# AVR128DB64 register map
Vendor: Atmel; File version: 1.0
CPU: other r0p0, little endian, no MPU, no FPU, 4 interrupt priority bits
Registers are 8-bit, read-write, reset 0x0 unless marked. A register's access mark holds for its fields unless they carry their own. Offsets are from the block's base; [hi:lo] are bit positions; {n}, {i} and the like mark numbered series; 'fields as' and 'values as' point back to an identical list.

## CRCSCAN
Base 0x00800120
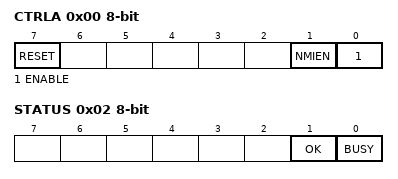
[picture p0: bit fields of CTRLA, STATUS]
0x00 CTRLA — Control A
  [7] RESET — Reset CRC scan
  [1] NMIEN — Enable NMI Trigger
  [0] ENABLE — Enable CRC scan
0x01 CTRLB — Control B
  [1:0] SRC — CRC Source
    0=FLASH (CRC on entire flash); 1=BOOTAPP (CRC on boot and appl section of flash); 2=BOOT (CRC on boot section of flash)
0x02 STATUS ro
  [1] OK — CRC Ok
  [0] BUSY — CRC Busy

## DAC0 — Digital to Analog Converter
Base 0x008006A0
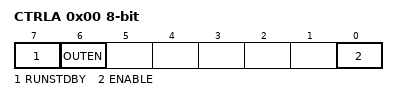
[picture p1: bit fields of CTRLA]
0x00 CTRLA — Control Register A
  [7] RUNSTDBY — Run in Standby Mode
  [6] OUTEN — Output Buffer Enable
  [0] ENABLE — DAC Enable
0x02 DATA 16-bit (reset mask 0xFF)
  [15:6] DATA

## GPR — General Purpose Registers
Base 0x0080001C
{0x0+i} GPR{i} (i=0..3) — General Purpose Register {i}

## LOCK — Lockbits
Base 0x00801040
0x00 KEY 32-bit (reset mask 0xFF) — Lock Key Bits
  [31:0] KEY — Lock Key
    0x5CC5C55C=NOLOCK (No locks); 0xA33A3AA3=RWLOCK (Read and write lock)

## MVIO — Multi-Voltage I/O
Base 0x008000C0
0x00 INTCTRL — Interrupt Control
  [0] VDDIO2IE — VDDIO2 Interrupt Enable
0x01 INTFLAGS — Interrupt Flags
  [0] VDDIO2IF — VDDIO2 Interrupt Flag
0x02 STATUS ro
  [0] VDDIO2S — VDDIO2 Status

## NVMCTRL — Non-volatile Memory Controller
Base 0x00801000
0x00 CTRLA — Control A
  [6:0] CMD — Command
    0=NONE (No Command); 1=NOOP (No Operation); 2=FLWR (Flash Write); 8=FLPER (Flash Page Erase); 9=FLMPER2 (Flash Multi-Page Erase 2 pages); 10=FLMPER4 (Flash Multi-Page Erase 4 pages); 11=FLMPER8 (Flash Multi-Page Erase 8 pages); 12=FLMPER16 (Flash Multi-Page Erase 16 pages); 13=FLMPER32 (Flash Multi-Page Erase 32 pages); 18=EEWR (EEPROM Write); 19=EEERWR (EEPROM Erase and Write); 24=EEBER (EEPROM Byte Erase); 25=EEMBER2 (EEPROM Multi-Byte Erase 2 bytes); 26=EEMBER4 (EEPROM Multi-Byte Erase 4 bytes); 27=EEMBER8 (EEPROM Multi-Byte Erase 8 bytes); 28=EEMBER16 (EEPROM Multi-Byte Erase 16 bytes); 29=EEMBER32 (EEPROM Multi-Byte Erase 32 bytes); 32=CHER (Chip Erase Command); 48=EECHER (EEPROM Erase Command)
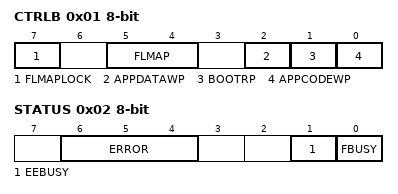
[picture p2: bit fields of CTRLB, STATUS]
0x01 CTRLB — Control B
  [7] FLMAPLOCK — Flash Mapping Lock
  [5:4] FLMAP — Flash Mapping in Data space
    {v}=SECTION{v} (Flash section {v}) (v=0..3)
  [2] APPDATAWP — Application Data Write Protect
  [1] BOOTRP — Boot Read Protect
  [0] APPCODEWP — Application Code Write Protect
0x02 STATUS ro
  [6:4] ERROR — Write error
    0=NOERROR; 1=ILLEGALCMD (Write command not selected); 2=ILLEGALSADDR (Write to section not allowed); 3=DOUBLESELECT (Selecting new write command while write command already seleted); 4=ONGOINGPROG (Starting a new programming operation before previous is completed)
  [1] EEBUSY — EEPROM busy
  [0] FBUSY — Flash busy
0x03 INTCTRL — Interrupt Control
  [0] EEREADY — EEPROM Ready
0x04 INTFLAGS — Interrupt Flags
  [0] EEREADY — EEPROM Ready
0x06 DATA 16-bit (reset mask 0xFF)
0x08 ADDR 32-bit (reset mask 0xFF) — Address

## OPAMP — Operational Amplifier System
Base 0x00800700
0x00 CTRLA — Control A
  [0] ENABLE — Op Amp System Enable
0x01 DBGCTRL — Debug Control
  [0] DBGRUN — Run in Debug Mode
0x02 TIMEBASE — Timebase Value
  [6:0] TIMEBASE
0x0F PWRCTRL — Power Control
  [0] IRSEL — Input Range Select
    0=FULL (Full Input Range); 1=REDUCED (Reduced Input Range)
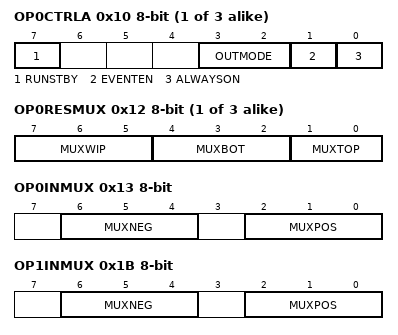
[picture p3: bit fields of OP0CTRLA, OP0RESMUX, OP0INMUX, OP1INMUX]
{0x10+8i} OP{i}CTRLA (i=0..2) — Op Amp {i} Control A
  [7] RUNSTBY — Run in Standby Mode
  [3:2] OUTMODE — Output Mode
    0=OFF (Output Driver Off); 1=NORMAL (Output Driver in Normal Mode)
  [1] EVENTEN — Enable Events
  [0] ALWAYSON
{0x11+8i} OP{i}STATUS (i=0..2) — Op Amp {i} Status
  [0] SETTLED ro
{0x12+8i} OP{i}RESMUX (i=0..2) — Op Amp {i} Resistor Ladder Multiplexer
  [7:5] MUXWIP — Multiplexer Wiper selector
    0=WIP0 (R1 = 15R, R2 = 1R, R2/R1 = 0.07); 1=WIP1 (R1 = 14R, R2 = 2R, R2/R1 = 0.14); 2=WIP2 (R1 = 12R, R2 = 4R, R2/R1 = 0.33); 3=WIP3 (R1 = 8R, R2 = 8R, R2/R1 = 1); 4=WIP4 (R1 = 6R, R2 = 10R, R2/R1 = 1.67); 5=WIP5 (R1 = 4R, R2 = 12R, R2/R1 = 3); 6=WIP6 (R1 = 2R, R2 = 14R, R2/R1 = 7); 7=WIP7 (R1 = 1R, R2 = 15R, R2/R1 = 15)
  [4:2] MUXBOT — Multiplexer Bottom
    0=OFF (Multiplexer off); 1=INP (Positive input pin for OPn); 2=INN (Negative input pin for OPn); 3=DAC (DAC output); 4=LINKOUT (Link OP[n-1] output); 5=GND (Ground)
  [1:0] MUXTOP — Multiplexer Top
    0=OFF (Multiplexer off); 1=OUT (OPn output); 2=VDD
0x13 OP0INMUX — Op Amp 0 Input Multiplexer
  [6:4] MUXNEG — Negative Input Multiplexer
    0=INN (Negative input pin for OPn); 1=WIP (Wiper from OPn's resistor ladder); 2=OUT (OPn output (unity gain)); 3=DAC (DAC output)
  [2:0] MUXPOS — Positive Input Multiplexer
    0=INP (Positive input pin for OPn); 1=WIP (Wiper from OPn's resistor ladder); 2=DAC (DAC output); 3=GND (Ground); 4=VDDDIV2 (VDD/2)
{0x14+8i} OP{i}SETTLE (i=0..2) — Op Amp {i} Settle
  [6:0] SETTLE — Settle Time
{0x15+8i} OP{i}CAL (i=0..2) — Op Amp {i} Calibration
  [7:0] CAL — Calibration (for input offset voltage)
0x1B OP1INMUX — Op Amp 1 Input Multiplexer
  [6:4] MUXNEG — Negative Input Multiplexer
    values as OP0INMUX.MUXNEG
  [2:0] MUXPOS — Positive Input Multiplexer
    0=INP (Positive input pin for OPn); 1=WIP (Wiper from OPn's resistor ladder); 2=DAC (DAC output); 3=GND (Ground); 4=VDDDIV2 (VDD/2); 5=LINKOUT (Output from OP0)
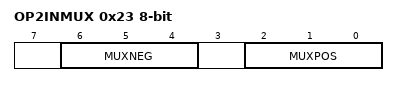
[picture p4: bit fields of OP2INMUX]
0x23 OP2INMUX — Op Amp 2 Input Multiplexer
  [6:4] MUXNEG — Negative Input Multiplexer
    values as OP0INMUX.MUXNEG
  [2:0] MUXPOS — Positive Input Multiplexer
    0=INP (Positive input pin for OPn); 1=WIP (Wiper from OPn's resistor ladder); 2=DAC (DAC output); 3=GND (Ground); 4=VDDDIV2 (VDD/2); 5=LINKOUT (Output from OP1); 6=LINKWIP (Wiper from OP0's resistor ladder)
